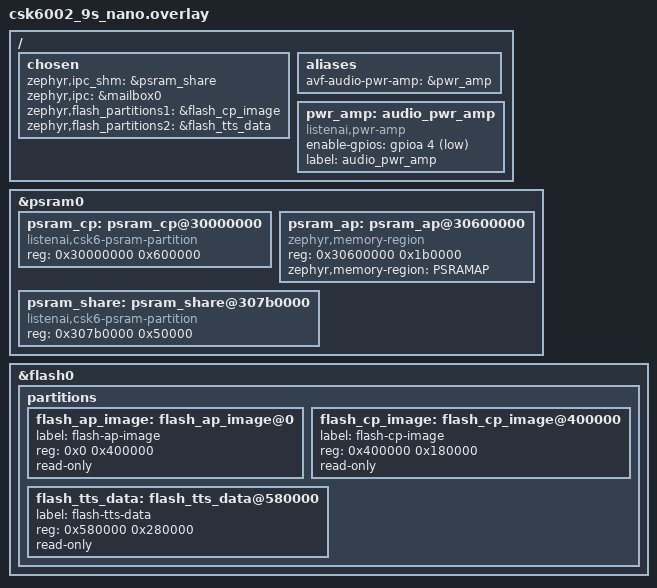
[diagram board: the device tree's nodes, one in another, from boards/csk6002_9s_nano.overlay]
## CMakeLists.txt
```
# SPDX-License-Identifier: Apache-2.0

cmake_minimum_required(VERSION 3.20.0)

find_package(Zephyr REQUIRED HINTS $ENV{ZEPHYR_BASE})
project(sample_aplay)
target_sources(app PRIVATE src/main.c src/tts_playback.c)

set(gen_dir ${ZEPHYR_BINARY_DIR}/include/generated)

generate_inc_file_for_target(
  app
  resource/csk6_default.tplg
  ${gen_dir}/dsp_tplg.inc
)

generate_inc_file_for_target(
  app
  resource/tts_data.bin
  ${gen_dir}/tts_data.inc
)

generate_inc_file_for_target(
  app
  resource/zephyr.bin
  ${gen_dir}/cp_firmware.inc
)

zephyr_linker_sources(SECTIONS custom-sections.ld)
```

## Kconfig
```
# SPDX-License-Identifier: Apache-2.0

DT_CHOSEN_Z_IPC_SHM := zephyr,ipc_shm
DT_CHOSEN_Z_FLASH_PARTITION1 := zephyr,flash_partitions1
DT_CHOSEN_Z_FLASH_PARTITION2 := zephyr,flash_partitions2
#SOF IPC MEMORY CONFIG
config AVF_IPC_SHM_BASE_ADDRESS
	default "$(dt_chosen_reg_addr_hex,$(DT_CHOSEN_Z_IPC_SHM))"

config AVF_IPC_SHM_SIZE
	default "$(dt_chosen_reg_size_hex,$(DT_CHOSEN_Z_IPC_SHM))"
	help
	  This option specifies size of the memory region to be used
	  for the SOF IPC shared memory

config FLASH_CP_IAMGE_ADDRESS
	hex "second core firmware space start address"
	default "$(dt_chosen_reg_addr_hex,$(DT_CHOSEN_Z_FLASH_PARTITION1))"

config FLASH_CP_IAMGE_SIZE
	hex "second core firmware space size"
	default "$(dt_chosen_reg_size_hex,$(DT_CHOSEN_Z_FLASH_PARTITION1))"

config FLASH_TTS_DATA_ADDRESS
	hex "TTS algorithm resource data space start address"
	default "$(dt_chosen_reg_addr_hex,$(DT_CHOSEN_Z_FLASH_PARTITION2))"

config FLASH_TTS_DATA_SIZE
	hex "TTS algorithm resource data space size"
	default "$(dt_chosen_reg_size_hex,$(DT_CHOSEN_Z_FLASH_PARTITION2))"

source "Kconfig.zephyr"
```

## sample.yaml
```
tests:
  sample.board.csk6.subsys.avf.alg_capacity.atts:
    platform_allow: csk6002_c3_nano csk6002_9s_nano csk6011a_nano
    tags: csk6
    build_only: true
    timeout: 30
    harness: console
    harness_config:
      type: multi_line
      regex:
      - "avf platform register success"
      - "tts playback start"
      - "tts playback over"
```

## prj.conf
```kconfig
CONFIG_PRINTK=y
CONFIG_DEBUG=y
CONFIG_LOG=y
CONFIG_LOG_MODE_IMMEDIATE=y
CONFIG_LOG_DETECT_MISSED_STRDUP=n
CONFIG_LOG_BACKEND_SHOW_COLOR=y
CONFIG_LOG_BACKEND_FORMAT_TIMESTAMP=y
CONFIG_LOG_BACKEND_UART=y
CONFIG_LOG_BACKEND_UART_OUTPUT_TEXT=y
CONFIG_MAIN_STACK_SIZE=2048

#system heap size,users can define it according to the actual usage
CONFIG_HEAP_MEM_POOL_SIZE=92160

#avf 
CONFIG_SOF_HOST=y
CONFIG_AVF_DSP_XIP=y
CONFIG_AVF_DSP_RUN_ADDRESS=0x68400000
CONFIG_AVF_DEBUG_LEVEL=1
CONFIG_AVF_USE_BINARY_ARRAY=y
CONFIG_AVF_MODULES_ALG_TTS=y

#IPM and GPIO for avf driver
CONFIG_IPM=y
CONFIG_GPIO=y

#cache
CONFIG_CACHE_MANAGEMENT=y
```

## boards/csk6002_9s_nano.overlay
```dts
/*
 * SPDX-License-Identifier: Apache-2.0
 */
/delete-node/ &psram_cp;
/delete-node/ &psram_ap;
/delete-node/ &psram_share;
/delete-node/ &wifi_driver_storage;
/delete-node/ &wifi_nvs_storage;
/delete-node/ &storage_partition;
/ {
	chosen {
		/*
		 * shared memory reserved for the inter-processor communication
		 */
		zephyr,ipc_shm = &psram_share;
		zephyr,ipc = &mailbox0;
		zephyr,flash_partitions1 = &flash_cp_image;
		zephyr,flash_partitions2 = &flash_tts_data;
	};

	aliases {
		avf-audio-pwr-amp = &pwr_amp;
	};
	pwr_amp: audio_pwr_amp{
		compatible = "listenai,pwr-amp";
		enable-gpios = <&gpioa 4 1>;
		label = "audio_pwr_amp";
		status = "okay";
	};

};

&psram0 {
	psram_cp: psram_cp@30000000 {
		compatible = "listenai,csk6-psram-partition";
		reg = <0x30000000 0x600000>;
		status = "okay";
	};
	psram_ap: psram_ap@30600000 {
		compatible = "zephyr,memory-region","listenai,csk6-psram-partition";
		reg = <0x30600000 0x1b0000>;
		status = "okay";
		zephyr,memory-region = "PSRAMAP";


	};
	psram_share: psram_share@307b0000 {
		compatible = "listenai,csk6-psram-partition";
		reg = <0x307b0000 0x50000>;
		status = "okay";
	};
};

&flash0 {

	partitions {
		flash_ap_image: flash_ap_image@0 {
			label = "flash-ap-image";
			reg = <0x0 0x400000>;
			read-only;
		};

		flash_cp_image: flash_cp_image@400000 {
			label = "flash-cp-image";
			reg = <0x400000 0x180000>;
			read-only;
		};

		flash_tts_data: flash_tts_data@580000 {
			label = "flash-tts-data";
			reg = <0x580000 0x280000>;
			read-only;
		};
	};
};
```

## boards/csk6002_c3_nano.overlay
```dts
/*
 * SPDX-License-Identifier: Apache-2.0
 */
/delete-node/ &psram_cp;
/delete-node/ &psram_ap;
/delete-node/ &psram_share;
/delete-node/ &boot_partition;
/delete-node/ &slot0_partition;
/delete-node/ &slot1_partition;
/delete-node/ &scratch_partition;
/delete-node/ &wifi_nvs_storage;
/delete-node/ &storage_partition;
/ {
	chosen {
		/*
		 * shared memory reserved for the inter-processor communication
		 */
		zephyr,ipc_shm = &psram_share;
		zephyr,ipc = &mailbox0;
		zephyr,flash_partitions1 = &flash_cp_image;
		zephyr,flash_partitions2 = &flash_tts_data;
		zephyr,code-partition = &flash_ap_image;
	};

	aliases {
		avf-audio-pwr-amp = &pwr_amp;
	};
	pwr_amp: audio_pwr_amp{
		compatible = "listenai,pwr-amp";
		enable-gpios = <&gpioa 4 1>;
		label = "audio_pwr_amp";
		status = "okay";
	};

};

&psram0 {
	psram_cp: psram_cp@30000000 {
		compatible = "listenai,csk6-psram-partition";
		reg = <0x30000000 0x600000>;
		status = "okay";
	};
	psram_ap: psram_ap@30600000 {
		compatible = "zephyr,memory-region","listenai,csk6-psram-partition";
		reg = <0x30600000 0x1b0000>;
		status = "okay";
		zephyr,memory-region = "PSRAMAP";


	};
	psram_share: psram_share@307b0000 {
		compatible = "listenai,csk6-psram-partition";
		reg = <0x307b0000 0x50000>;
		status = "okay";
	};
};

&flash0 {

	partitions {
		flash_ap_image: flash_ap_image@0 {
			label = "flash-ap-image";
			reg = <0x0 0x400000>;
			read-only;
		};

		flash_cp_image: flash_cp_image@400000 {
			label = "flash-cp-image";
			reg = <0x400000 0x180000>;
			read-only;
		};

		flash_tts_data: flash_tts_data@580000 {
			label = "flash-tts-data";
			reg = <0x580000 0x280000>;
			read-only;
		};
	};
};
```

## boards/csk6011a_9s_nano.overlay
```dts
/*
 * SPDX-License-Identifier: Apache-2.0
 */
 /delete-node/ &psram_cp;
 /delete-node/ &psram_ap;
 /delete-node/ &psram_share;
 /delete-node/ &wifi_driver_storage;
 /delete-node/ &wifi_nvs_storage;
 /delete-node/ &storage_partition;
 / {
	 chosen {
		 /*
		  * shared memory reserved for the inter-processor communication
		  */
		 zephyr,ipc_shm = &psram_share;
		 zephyr,ipc = &mailbox0;
		 zephyr,flash_partitions1 = &flash_cp_image;
		 zephyr,flash_partitions2 = &flash_tts_data;
	 };
 
	 aliases {
		 avf-audio-pwr-amp = &pwr_amp;
	 };
	 pwr_amp:audio_pwr_amp{
		 compatible = "listenai,pwr-amp";
		 enable-gpios = <&gpioa 4 1>;
		 label = "audio_pwr_amp";	
		 status = "okay";
	 };
 
 };
 
 &psram0{
	psram_cp: psram_cp@30000000 {
		compatible = "listenai,csk6-psram-partition";
		reg = < 0x30000000 0x600000 >;
		status = "okay";
	};
	psram_ap: psram_ap@30600000 {
		compatible = "zephyr,memory-region","listenai,csk6-psram-partition";
		reg = <0x30600000 0x1b0000>;
		status = "okay";
		zephyr,memory-region = "PSRAMAP";


	};
	psram_share: psram_share@307b0000 {
		compatible = "listenai,csk6-psram-partition";
		reg = < 0x307b0000 0x50000 >;
		status = "okay";
	};
};

&flash0 {

	partitions {
		flash_ap_image:flash_ap_image@0{
			label = "flash-ap-image";
			reg = < 0x0 0x400000 >;
			read-only;
		};

		flash_cp_image: flash_cp_image@400000 {
			label = "flash-cp-image";
			reg = < 0x400000 0x180000 >;
			read-only;
		};

		flash_tts_data: flash_tts_data@580000 {
			label = "flash-tts-data";
			reg = < 0x580000 0x280000 >;
			read-only;
		};
	};
};
```

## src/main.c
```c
/*
 *
 * SPDX-License-Identifier: Apache-2.0
 */

#include <zephyr.h>
#include <avf/framework/avf_platform.h>
#include "dsp_resource.h"

#include "pwr_amp.c"

#define TTS_STRING "这是一段TTS测试语音"

extern int  atts_playback(const char* tts_string);

void main(void)
{
	
	if(NULL == avf_stream_platform_register(NULL, 0, dsp_tplg,
				     sizeof(dsp_tplg))){
		printk("avf platform register failed,exit.\n");
		return;
	}
	printk("avf platform register success\n");

	/*Enable audio power-amp*/
	audio_pwr_amp_init();
    audio_pwr_amp_enbale();

	printk("tts playback start\n");
	if(0 != atts_playback(TTS_STRING)){
		printk("tts playback failed\n");
		return;
		
	}
	printk("tts playback over\n");
}
```

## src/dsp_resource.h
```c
/*
 * SPDX-License-Identifier: Apache-2.0
 */
#pragma GCC push_options
#pragma GCC optimize("O0")

static const unsigned char dsp_tplg[] = {
#include "dsp_tplg.inc"
};

__attribute__((section(".tts_data.text"))) static const unsigned char tts_data[] = {
#include "tts_data.inc"
};

__attribute__((section(".cp_image.text"))) static const unsigned char cp_firmware[] = {
#include "cp_firmware.inc"
};

#pragma GCC pop_options
```

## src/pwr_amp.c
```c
#include <zephyr.h>
#include <device.h>
#include <drivers/gpio.h>

#if defined(__ZEPHYR__) && (DT_NODE_HAS_STATUS(DT_ALIAS(avf_audio_pwr_amp), okay))

#define AVF_AUDIO_PWR_AMP DT_GPIO_LABEL(DT_ALIAS(avf_audio_pwr_amp), enable_gpios)
#define AVF_AUDIO_PWR_AMP_PIN DT_GPIO_PIN(DT_ALIAS(avf_audio_pwr_amp), enable_gpios)
#define AVF_AUDIO_PWR_AMP_FLAGS DT_GPIO_FLAGS(DT_ALIAS(avf_audio_pwr_amp), enable_gpios)

static inline void audio_pwr_amp_enbale(void)
{
	const struct device *dev;

	dev = device_get_binding(AVF_AUDIO_PWR_AMP);
	if (dev == NULL) {
		return;
	}
	gpio_pin_set(dev, AVF_AUDIO_PWR_AMP_PIN, 1);
}

static inline void audio_pwr_amp_disable(void)
{
	const struct device *dev;

	dev = device_get_binding(AVF_AUDIO_PWR_AMP);
	if (dev == NULL) {
		return;
	}
	gpio_pin_set(dev, AVF_AUDIO_PWR_AMP_PIN, 0);
}

static inline void audio_pwr_amp_init(void)
{
	int ret;
	const struct device *dev;

	dev = device_get_binding(AVF_AUDIO_PWR_AMP);
	if (dev == NULL) {
		return;
	}

	ret = gpio_pin_configure(dev, AVF_AUDIO_PWR_AMP_PIN, GPIO_OUTPUT_ACTIVE);
	if (ret < 0) {
		return;
	}
}

#else
#warning "The amplifier pins are not defined"

static inline void audio_pwr_amp_enbale(void)
{
}
static inline void audio_pwr_amp_disable(void)
{
}
static inline void audio_pwr_amp_init(void)
{
}

#endif
```

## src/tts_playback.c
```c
#include <device.h>
#include <devicetree.h>
#include <zephyr.h>
#include <fs/fs.h>
#include <drivers/uart.h>
#include <usb/usb_device.h>
#include <avf/slogger.h>
#include <avf/modules/tts/tts_playback.h>

static K_SEM_DEFINE(sem_tts_playover, 0, 1);
#define TTS_PLAY_TIMOUTMS (60000)
static void audio_tts_event_wrap(void *priv, atts_notify_event_flags_t event)
{
	k_sem_give(&sem_tts_playover);
	printk("atts play over!\n");
}

int atts_playback(const char *tts_string)
{
	atts_t *atts_handle;
	amedia_fmt_t fmt;
	int iret = 0;

	atts_handle = atts_create(AVF_STREAM_DIRECTION_PLAYBACK);

	if (atts_handle == NULL) {
		SLOGE(LOG_TAG, "[%s %d]atts_create failed!", __FUNCTION__, __LINE__);
		return -1;
	}

	memset(&fmt, 0, sizeof(amedia_fmt_t));

	atts_set_fmt(atts_handle, &fmt);
	atts_start(atts_handle);
	atts_notify_event_register(atts_handle, audio_tts_event_wrap, ATTS_NOTIFY_PLAYOVER,
				   atts_handle);

	atts_play(atts_handle, tts_string, strlen(tts_string));

	if (0 != k_sem_take(&sem_tts_playover, K_MSEC(TTS_PLAY_TIMOUTMS))) {
		printk("atts play timout!\n");
		iret = -2;
	} else {
		printk("atts play success!\n");
	}

	atts_stop(atts_handle);
	atts_destroy(atts_handle);

	return iret;
}
```
